# f29h85x_rtdma_regs register map
Vendor: Texas Instruments
Peripheral module from a debugger description file (folder HSM).
Registers are 32-bit, read-write, no defined reset value unless marked. A register's access mark holds for its fields unless they carry their own. Offsets are as the file gives them; lines under a group give offsets from that group; [hi:lo] are bit positions; {n}, {i} and the like mark numbered series; 'fields as' and 'values as' point back to an identical list; <NAME> marks a mode.

## RTDMA_REGS — RTDMA Registers
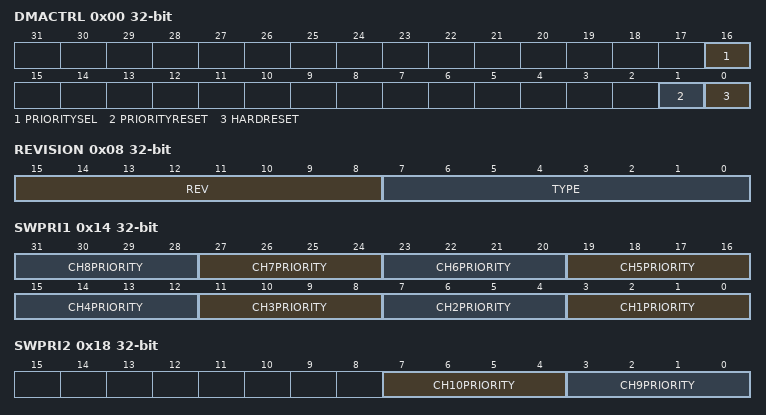
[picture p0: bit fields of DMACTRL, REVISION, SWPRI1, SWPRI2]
0x00 DMACTRL — DMA Control Register
  [16] PRIORITYSEL — The priority select bit
  [1] PRIORITYRESET — Priority Reset Bit
  [0] HARDRESET — Hard Reset Bit
0x04 DEBUGCTRL — Debug Control Register
  [15] FREE — Debug Mode Bit
0x08 REVISION ro — RTDMA Revision Control Register
  [15:8] REV — RTDMA Revision
  [7:0] TYPE — RTDMA Type
0x14 SWPRI1 — Software Priority Configuration Register 1
  [4n-1:4n-4] CH{n}PRIORITY (n=1..8) — Ch{n} Priority Configuration
0x18 SWPRI2 — Software Priority Configuration Register 2
  [7:4] CH10PRIORITY — Ch10 Priority Configuration
  [3:0] CH9PRIORITY — Ch9 Priority Configuration
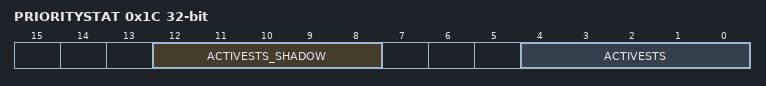
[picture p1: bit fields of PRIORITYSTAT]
0x1C PRIORITYSTAT ro — Priority Status Register
  [12:8] ACTIVESTS_SHADOW — Active Channel Status Shadow Bits
  [4:0] ACTIVESTS — Active Channel Status Bits
0x40 DMACFG_LOCK — Channel Configuration Temporary Lock
  [0] LOCK — Temporary Lock
0x44 DMACFG_COMMIT — Channel Configuration Permanent Commit
  [0] COMMIT — Permanent Commit
